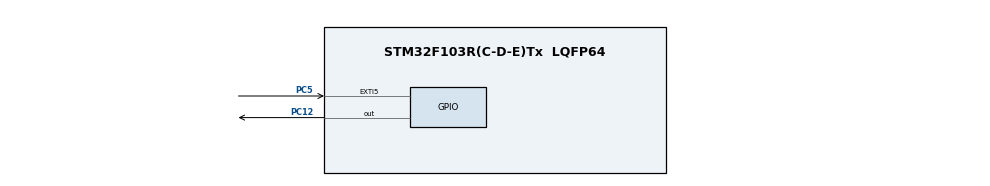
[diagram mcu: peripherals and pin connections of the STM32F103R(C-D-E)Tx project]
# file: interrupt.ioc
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Mcu.Family=STM32F1
Mcu.Name=STM32F103R(C-D-E)Tx
Mcu.Package=LQFP64
NVIC.EXTI9_5_IRQn=true\:15\:0\:true\:false\:true\:true\:true\:true
NVIC.PriorityGroup=NVIC_PRIORITYGROUP_4
PC12.GPIO_ModeDefaultOutputPP=GPIO_MODE_OUTPUT_PP
PC12.GPIO_Speed=GPIO_SPEED_FREQ_LOW
PC12.PinState=GPIO_PIN_RESET
PC12.Signal=GPIO_Output
PC5.GPIO_ModeDefaultEXTI=GPIO_MODE_IT_FALLING
PC5.GPIO_PuPd=GPIO_PULLUP
PC5.Signal=GPXTI5
ProjectManager.HeapSize=0x200
ProjectManager.StackSize=0x400
ProjectManager.TargetToolchain=MDK-ARM V5.32
RCC.APB1Freq_Value=8000000
RCC.APB2Freq_Value=8000000
VP_SYS_VS_ND.Mode=No_Debug
board=custom

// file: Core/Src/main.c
/* USER CODE BEGIN Header */
/**
  ******************************************************************************
  * @file           : main.c
  * @brief          : Main program body
  ******************************************************************************
  * @attention
  *
  * Copyright (c) 2022 STMicroelectronics.
  * All rights reserved.
  *
  * This software is licensed under terms that can be found in the LICENSE file
  * in the root directory of this software component.
  * If no LICENSE file comes with this software, it is provided AS-IS.
  *
  ******************************************************************************
  */
/* USER CODE END Header */
#include "main.h"

void SystemClock_Config(void);
static void MX_GPIO_Init(void);
void KEY_DEBOUNCE_change_Hz(uint16_t GPIO_PIN);
/* USER CODE BEGIN PFP */
volatile uint8_t BlinkSpeed=0;//ָʾ����˸Ƶ��
/* USER CODE END PFP */

int main(void)
{

  /* MCU Configuration--------------------------------------------------------*/

  /* Reset of all peripherals, Initializes the Flash interface and the Systick. */
  HAL_Init();

  /* Configure the system clock */
  SystemClock_Config();

  /* Initialize all configured peripherals */
  MX_GPIO_Init();

  /* Infinite loop */
  while (1)
  {

    /* USER CODE BEGIN 3 */
		if(BlinkSpeed==0){
				HAL_GPIO_TogglePin(GPIOC,GPIO_PIN_12);
				HAL_Delay(500);//2Hz��˸
		}else if(BlinkSpeed==1){
			HAL_GPIO_TogglePin(GPIOC,GPIO_PIN_12);
				HAL_Delay(100);//10Hz��˸
  }else{
		HAL_GPIO_TogglePin(GPIOC,GPIO_PIN_12);
				HAL_Delay(50);//20Hz��˸
	}
}
  /* USER CODE END 3 */
}

void SystemClock_Config(void)
{
  RCC_OscInitTypeDef RCC_OscInitStruct = {0};
  RCC_ClkInitTypeDef RCC_ClkInitStruct = {0};

  /** Initializes the RCC Oscillators according to the specified parameters
  * in the RCC_OscInitTypeDef structure.
  */
  RCC_OscInitStruct.OscillatorType = RCC_OSCILLATORTYPE_HSI;
  RCC_OscInitStruct.HSIState = RCC_HSI_ON;
  RCC_OscInitStruct.HSICalibrationValue = RCC_HSICALIBRATION_DEFAULT;
  RCC_OscInitStruct.PLL.PLLState = RCC_PLL_NONE;
  if (HAL_RCC_OscConfig(&RCC_OscInitStruct) != HAL_OK)
  {
    Error_Handler();
  }

  /** Initializes the CPU, AHB and APB buses clocks
  */
  RCC_ClkInitStruct.ClockType = RCC_CLOCKTYPE_HCLK|RCC_CLOCKTYPE_SYSCLK
                              |RCC_CLOCKTYPE_PCLK1|RCC_CLOCKTYPE_PCLK2;
  RCC_ClkInitStruct.SYSCLKSource = RCC_SYSCLKSOURCE_HSI;
  RCC_ClkInitStruct.AHBCLKDivider = RCC_SYSCLK_DIV1;
  RCC_ClkInitStruct.APB1CLKDivider = RCC_HCLK_DIV1;
  RCC_ClkInitStruct.APB2CLKDivider = RCC_HCLK_DIV1;

  if (HAL_RCC_ClockConfig(&RCC_ClkInitStruct, FLASH_LATENCY_0) != HAL_OK)
  {
    Error_Handler();
  }
}

static void MX_GPIO_Init(void)
{
  GPIO_InitTypeDef GPIO_InitStruct = {0};

  /* GPIO Ports Clock Enable */
  __HAL_RCC_GPIOC_CLK_ENABLE();

  /*Configure GPIO pin Output Level */
  HAL_GPIO_WritePin(GPIOC, GPIO_PIN_12, GPIO_PIN_RESET);

  /*Configure GPIO pin : PC5 */
  GPIO_InitStruct.Pin = GPIO_PIN_5;
  GPIO_InitStruct.Mode = GPIO_MODE_IT_FALLING;
  GPIO_InitStruct.Pull = GPIO_PULLUP;
  HAL_GPIO_Init(GPIOC, &GPIO_InitStruct);

  /*Configure GPIO pin : PC12 */
  GPIO_InitStruct.Pin = GPIO_PIN_12;
  GPIO_InitStruct.Mode = GPIO_MODE_OUTPUT_PP;
  GPIO_InitStruct.Pull = GPIO_NOPULL;
  GPIO_InitStruct.Speed = GPIO_SPEED_FREQ_LOW;
  HAL_GPIO_Init(GPIOC, &GPIO_InitStruct);

  /* EXTI interrupt init*/
  HAL_NVIC_SetPriority(EXTI9_5_IRQn, 15, 0);
  HAL_NVIC_EnableIRQ(EXTI9_5_IRQn);

}

/* USER CODE BEGIN 4 */
void KEY_DEBOUNCE_change_Hz(uint16_t GPIO_PIN){
		if(HAL_GPIO_ReadPin(GPIOC,GPIO_PIN)==GPIO_PIN_RESET)
				{
					HAL_Delay(10);
					if(HAL_GPIO_ReadPin(GPIOC,GPIO_PIN)==GPIO_PIN_RESET){
							if(BlinkSpeed>=2){
				BlinkSpeed=0;
				}else{
					BlinkSpeed++;
				}
					}
					while(HAL_GPIO_ReadPin(GPIOC,GPIO_PIN)==GPIO_PIN_RESET);
				}
}
void HAL_GPIO_EXTI_Callback(uint16_t GPIO_Pin){
			if(GPIO_Pin==GPIO_PIN_5){
				KEY_DEBOUNCE_change_Hz(GPIO_PIN_5);
			}
}
/* USER CODE END 4 */

void Error_Handler(void)
{
  __disable_irq();
  while (1)
  {
  }
}
